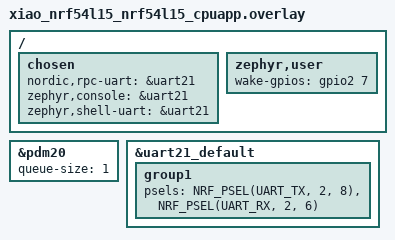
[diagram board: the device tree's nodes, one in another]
/* 
 * Board overlay for XIAO nRF54L15 blink sample
 * 
 * The built-in LED (led0) is already defined in the board definition,
 * so no additional configuration is needed for the basic blink sample.
 */

&pdm20 {
	queue-size = <1>;
};

/ {
	chosen {
		nordic,rpc-uart = &uart21;
		zephyr,console = &uart21;
		zephyr,shell-uart = &uart21;
	};

	zephyr,user {
		wake-gpios = <&gpio2 7 0>;
	};
};
/delete-node/ &{/pin-controller/uart21_default/group2/};

&uart21_default {
	group1 {
		psels = <NRF_PSEL(UART_TX, 2, 8)>, <NRF_PSEL(UART_RX, 2, 6)>;
	};
};
